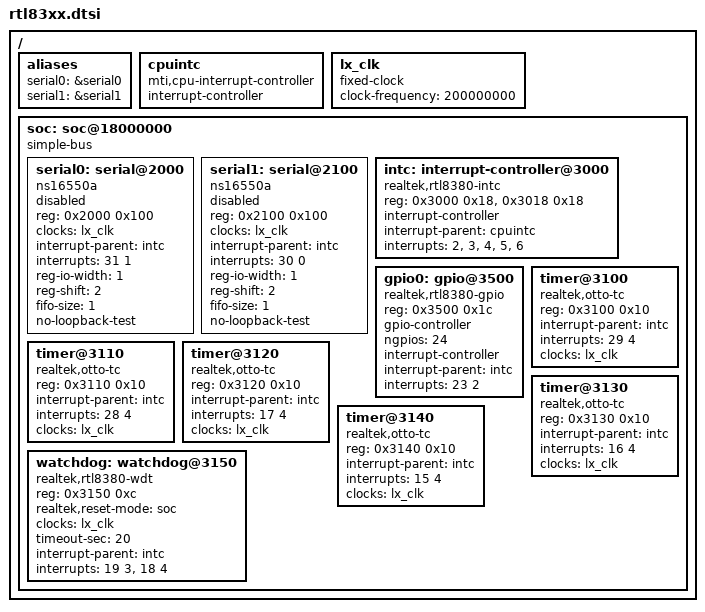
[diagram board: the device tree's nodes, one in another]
// SPDX-License-Identifier: GPL-2.0-or-later OR BSD-2-Clause

/ {
	#address-cells = <1>;
	#size-cells = <1>;

	aliases {
		serial0 = &serial0;
		serial1 = &serial1;
	};

	cpuintc: cpuintc {
		compatible = "mti,cpu-interrupt-controller";
		#address-cells = <0>;
		#interrupt-cells = <1>;
		interrupt-controller;
	};

	lx_clk: lx_clk {
		compatible = "fixed-clock";
		#clock-cells = <0>;
		clock-frequency = <200000000>;
	};

	soc: soc@18000000 {
		compatible = "simple-bus";
		#address-cells = <1>;
		#size-cells = <1>;
		ranges = <0x0 0x18000000 0x10000>;

		serial0: serial@2000 {
			compatible = "ns16550a";
			reg = <0x2000 0x100>;

			clocks = <&lx_clk>;

			interrupt-parent = <&intc>;
			interrupts = <31 1>;

			reg-io-width = <1>;
			reg-shift = <2>;
			fifo-size = <1>;
			no-loopback-test;

			status = "disabled";
		};

		serial1: serial@2100 {
			compatible = "ns16550a";
			reg = <0x2100 0x100>;

			clocks = <&lx_clk>;

			interrupt-parent = <&intc>;
			interrupts = <30 0>;

			reg-io-width = <1>;
			reg-shift = <2>;
			fifo-size = <1>;
			no-loopback-test;

			status = "disabled";
		};

		intc: interrupt-controller@3000 {
			compatible = "realtek,rtl8380-intc", "realtek,rtl-intc";
			reg = <0x3000 0x18>, <0x3018 0x18>;
			interrupt-controller;
			#interrupt-cells = <2>;

			interrupt-parent = <&cpuintc>;
			interrupts = <2>, <3>, <4>, <5>, <6>;
		};

		gpio0: gpio@3500 {
			compatible = "realtek,rtl8380-gpio", "realtek,otto-gpio";
			reg = <0x3500 0x1c>;

			gpio-controller;
			#gpio-cells = <2>;
			ngpios = <24>;

			interrupt-controller;
			#interrupt-cells = <2>;
			interrupt-parent = <&intc>;
			interrupts = <23 2>;
		};

		timer@3100 {
			compatible = "realtek,otto-tc";
			reg = <0x3100 0x10>;
			interrupt-parent = <&intc>;
			interrupts = <29 4>;
			clocks = <&lx_clk>;
			clock-names = "bus";
		};

		timer@3110 {
			compatible = "realtek,otto-tc";
			reg = <0x3110 0x10>;
			interrupt-parent = <&intc>;
			interrupts = <28 4>;
			clocks = <&lx_clk>;
			clock-names = "bus";
		};

		timer@3120 {
			compatible = "realtek,otto-tc";
			reg = <0x3120 0x10>;
			interrupt-parent = <&intc>;
			interrupts = <17 4>;
			clocks = <&lx_clk>;
			clock-names = "bus";
		};

		timer@3130 {
			compatible = "realtek,otto-tc";
			reg = <0x3130 0x10>;
			interrupt-parent = <&intc>;
			interrupts = <16 4>;
			clocks = <&lx_clk>;
			clock-names = "bus";
		};

		timer@3140 {
			compatible = "realtek,otto-tc";
			reg = <0x3140 0x10>;
			interrupt-parent = <&intc>;
			interrupts = <15 4>;
			clocks = <&lx_clk>;
			clock-names = "bus";
		};

		watchdog: watchdog@3150 {
			compatible = "realtek,rtl8380-wdt";
			reg = <0x3150 0xc>;

			realtek,reset-mode = "soc";

			clocks = <&lx_clk>;
			timeout-sec = <20>;

			interrupt-parent = <&intc>;
			interrupt-names = "phase1", "phase2";
			interrupts = <19 3>, <18 4>;
		};
	};
};
